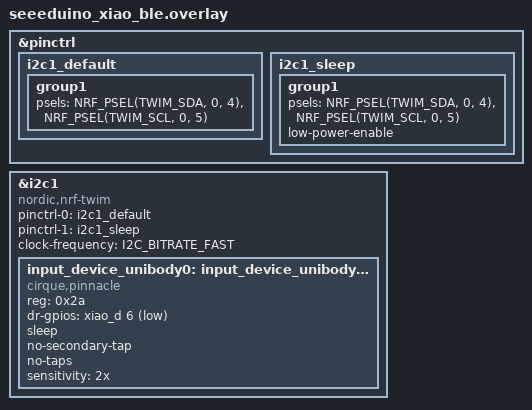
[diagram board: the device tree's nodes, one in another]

/**
 * Generated by Shield Wizard for ZMK
 * Applies to shield "cirquei2ctest" with board "seeeduino_xiao_ble" only
 */

//
// ======== i2c1 ========
//

// pin control for i2c1
// - SDA on D4
// - SCL on D5
&pinctrl {
    /* configuration for i2c1 device, default state */
    i2c1_default: i2c1_default {
        group1 {
            psels = <NRF_PSEL(TWIM_SDA, 0, 4)>,
                    <NRF_PSEL(TWIM_SCL, 0, 5)>;
        };
    };
    /* configuration for i2c1 device, sleep state */
    i2c1_sleep: i2c1_sleep {
        group1 {
            psels = <NRF_PSEL(TWIM_SDA, 0, 4)>,
                    <NRF_PSEL(TWIM_SCL, 0, 5)>;
            low-power-enable;
        };
    };
};
&i2c1 {
  compatible = "nordic,nrf-twim";
  status = "okay";
  pinctrl-0 = <&i2c1_default>;
  pinctrl-1 = <&i2c1_sleep>;
  pinctrl-names = "default", "sleep";
  clock-frequency = <I2C_BITRATE_FAST>;
};

// devices on i2c1

&i2c1 {
    input_device_unibody0: input_device_unibody0@2a {
        status = "okay";
        compatible = "cirque,pinnacle";
        reg = <0x2a>;
        dr-gpios = <&xiao_d 6 (GPIO_ACTIVE_LOW | GPIO_PULL_UP)>;
        sleep;
        no-secondary-tap;
        no-taps;
        sensitivity = "2x";
    };
};
